# BL808 register map
File version: 0.1
Registers are access not given, no defined reset value unless marked. A register's access mark holds for its fields unless they carry their own. Offsets are from the block's base; [hi:lo] are bit positions; {n}, {i} and the like mark numbered series.

## DSI
Base 0x3001A100
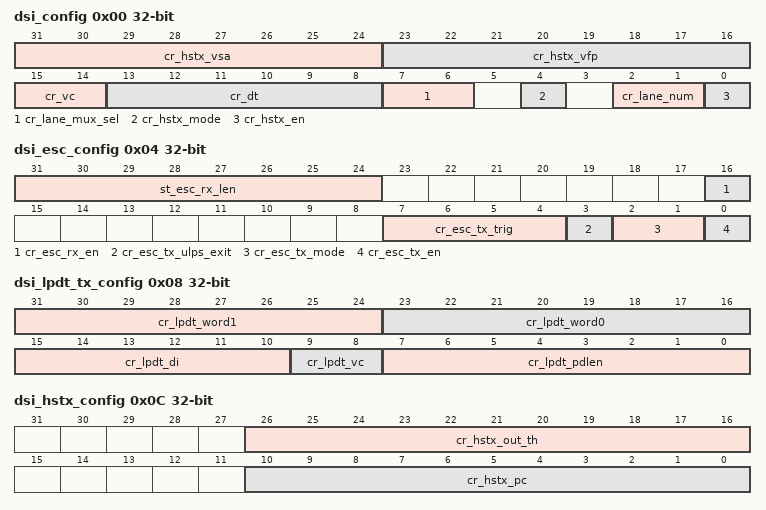
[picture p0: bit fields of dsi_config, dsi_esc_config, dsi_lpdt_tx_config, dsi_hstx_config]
0x00 dsi_config
  [31:24] cr_hstx_vsa rw — HSTX Vertical Sync Active width
  [23:16] cr_hstx_vfp rw — HSTX Vertical Front Porch width
  [15:14] cr_vc rw — Virtual Channel number
  [13:8] cr_dt rw — Data Type 6'h2C: YUV422, 8-bit 6'h0E: RGB565 6'h2E: RGB666, loosely packed 6'h3E: RGB888 Others: Reserved
  [7:6] cr_lane_mux_sel rw — Controls lane order 2'd0: {lane3, lane2, lane1, lane0} (no lane is switched) 2'd1: {lane2, lane1, lane3, lane0} 2'd2: {lane1, lane3, lane2, lane0} 2'd3: {lane3, lane1, lane2, lane0}
  [4] cr_hstx_mode rw — HSTX mode select 1'b0: Sync Event mode 1'b1: Sync Pulse mode
  [2:1] cr_lane_num rw — Lane number configuration 2'd0: 1-lane MIPI TX 2'd1: 2-lane MIPI TX 2'd2: 4-lane MIPI TX 2'd3: Reserved
  [0] cr_hstx_en rw — HSTX function enable signal
0x04 dsi_esc_config
  [31:24] st_esc_rx_len ro — Escape RX length received (Include packet header/data/footer) (unit: byte)
  [16] cr_esc_rx_en rw — Escape RX enable signal
  [7:4] cr_esc_tx_trig rw — Escape TX trigger command
  [3] cr_esc_tx_ulps_exit write-once — Escape TX ULPS exit signal trigger
  [2:1] cr_esc_tx_mode rw — Escape TX mode select 2'd0: LPDT 2'd1: Trigger command 2'd2: ULPS Enable 2'd3: ULPS Disable
  [0] cr_esc_tx_en write-once — Escape TX enable signal
0x08 dsi_lpdt_tx_config rw
  [31:24] cr_lpdt_word1 — LPDT TX word 1
  [23:16] cr_lpdt_word0 — LPDT TX word 0
  [15:10] cr_lpdt_di — LPDT TX data identifier
  [9:8] cr_lpdt_vc — LPDT TX virtual channel
  [7:0] cr_lpdt_pdlen — LPDT TX packet data length (exclude packet header & footer) (unit: byte)
0x0C dsi_hstx_config
  [26:16] cr_hstx_out_th rw — Line buffer threshold for controller to start transmitting each line (unit: pixel) Formula: th = ceil( W * (1 - Fdp*BPP/Fhs/Ln) ) th: cr_hstx_out_th W: Frame width Fdp: Display (dp_dvp_tsrc) clock rate Fhs: DSI byte clock rate (dsi_bit_clk/8 or mipipll_clk/8) BPP: Byte-per-pixel (equals 3 for RGB888 & RGB666; equals 2 for RGB565 & YUV422_8) Ln: DSI lane number (controlled by cr_lane_num) Note: The minimum value is 6 for synchronization concern (Set to 6 if the formula result is negative or less than 6)
  [10:0] cr_hstx_pc rw — Pixel count of each line (frame width) (unit:pixel) Note: Pixel count should not exceed 1280 (720p) and should be a multiple of 4
0x10 dsi_int_status
  [13:0] dsi_int_status ro — [13]: FIFO Error (check 0x60[7:4] for detail) [12]: Pixel Count Too Large Error [11]: Pixel Count Too Small Error [10]: Buffer Underrun Error [9]: Buffer Overrun Error [8]: RX LPDT FIFO ready [7]: TX LPDT FIFO ready [6:3]: RX Trigger Command [2]: RX ULPS Command [1]: RX LPDT End [0]: TX Escape Command End
0x14 dsi_int_mask
  [13:0] dsi_int_mask rw — [13]: FIFO Error (check 0x60[7:4] for detail) [12]: Pixel Count Too Large Error [11]: Pixel Count Too Small Error [10]: Buffer Underrun Error [9]: Buffer Overrun Error [8]: RX LPDT FIFO ready [7]: TX LPDT FIFO ready [6:3]: RX Trigger Command [2]: RX ULPS Command [1]: RX LPDT End [0]: TX Escape Command End
0x18 dsi_int_clear
  [13:0] dsi_int_clear write-once — [13]: FIFO Error (check 0x60[7:4] for detail) [12]: Pixel Count Too Large Error [11]: Pixel Count Too Small Error [10]: Buffer Underrun Error [9]: Buffer Overrun Error [8]: RX LPDT FIFO ready [7]: TX LPDT FIFO ready [6:3]: RX Trigger Command [2]: RX ULPS Command [1]: RX LPDT End [0]: TX Escape Command End
0x1C dsi_int_enable
  [13:0] dsi_int_enable rw — [13]: FIFO Error (check 0x60[7:4] for detail) [12]: Pixel Count Too Large Error [11]: Pixel Count Too Small Error [10]: Buffer Underrun Error [9]: Buffer Overrun Error [8]: RX LPDT FIFO ready [7]: TX LPDT FIFO ready [6:3]: RX Trigger Command [2]: RX ULPS Command [1]: RX LPDT End [0]: TX Escape Command End
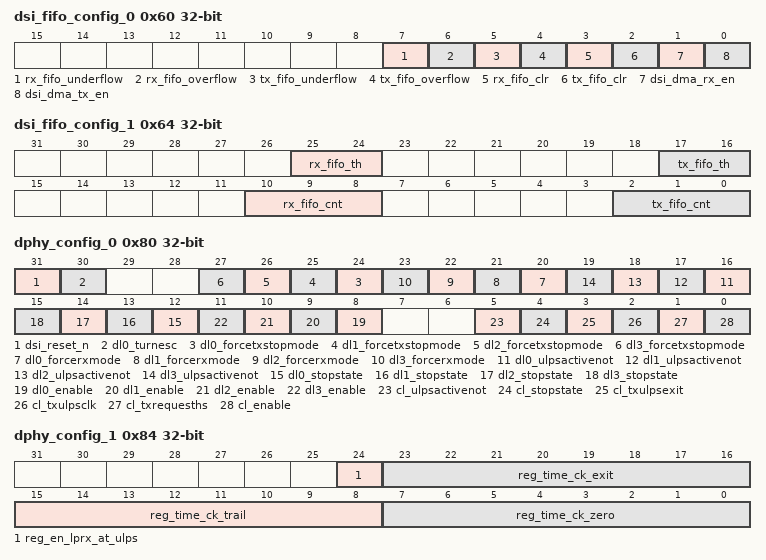
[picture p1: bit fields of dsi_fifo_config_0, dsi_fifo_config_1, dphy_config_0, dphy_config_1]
0x60 dsi_fifo_config_0
  [7] rx_fifo_underflow ro — Underflow flag of RX FIFO, can be cleared by rx_fifo_clr
  [6] rx_fifo_overflow ro — Overflow flag of RX FIFO, can be cleared by rx_fifo_clr
  [5] tx_fifo_underflow ro — Underflow flag of TX FIFO, can be cleared by tx_fifo_clr
  [4] tx_fifo_overflow ro — Overflow flag of TX FIFO, can be cleared by tx_fifo_clr
  [3] rx_fifo_clr write-once — Clear signal of RX FIFO
  [2] tx_fifo_clr write-once — Clear signal of TX FIFO
  [1] dsi_dma_rx_en rw — Enable signal of dma_rx_req/ack interface
  [0] dsi_dma_tx_en rw — Enable signal of dma_tx_req/ack interface
0x64 dsi_fifo_config_1
  [25:24] rx_fifo_th rw — RX FIFO threshold, dma_rx_req will not be asserted if tx_fifo_cnt is less than this value
  [17:16] tx_fifo_th rw — TX FIFO threshold, dma_tx_req will not be asserted if tx_fifo_cnt is less than this value
  [10:8] rx_fifo_cnt ro — RX FIFO available count
  [2:0] tx_fifo_cnt ro — TX FIFO available count
0x68 dsi_fifo_wdata wo
  [31:0] dsi_fifo_wdata
0x6C dsi_fifo_rdata ro
  [31:0] dsi_fifo_rdata
0x80 dphy_config_0
  [31] dsi_reset_n rw — MIPI DSI D-PHY reset pin
  [30] dl0_turnesc write-once — Data lane0 Bus Turnaround
  [n+24] dl{n}_forcetxstopmode rw (n=0..3) — Force Lane{n} to Generate Stop State
  [n+20] dl{n}_forcerxmode rw (n=0..3) — Enables the reverse escape LP receiver. Lane{n} immediately transitions to receive mode.
  [n+16] dl{n}_ulpsactivenot ro (n=0..3) — Data lane{n} is NOT in the ULP state
  [n+12] dl{n}_stopstate ro (n=0..3) — Data lane{n} is in Stop state
  [n+8] dl{n}_enable rw (n=0..3) — Data lane{n} enable
  [5] cl_ulpsactivenot ro — Clock lane is NOT in the ULP state
  [4] cl_stopstate ro — Clock lane is in Stop state
  [3] cl_txulpsexit write-once — Clock lane Transmit ULP Exit Sequence
  [2] cl_txulpsclk rw — Clock lane Transmit Ultra-Low Power State
  [1] cl_txrequesths rw — Clock lane High-Speed Transmit Request
  [0] cl_enable rw — Clock lane enable
0x84 dphy_config_1
  [24] reg_en_lprx_at_ulps rw — MIPI DSI D-PHY control register - reg_en_lprx_at_ulps
  [23:16] reg_time_ck_exit rw — MIPI DSI D-PHY control register - reg_time_ck_exit (tx_clk_esc) txclkesc: 40M, datarate: 800Mbps
  [15:8] reg_time_ck_trail rw — MIPI DSI D-PHY control register - reg_time_ck_trail (tx_clk_esc)
  [7:0] reg_time_ck_zero rw — MIPI DSI D-PHY control register - reg_time_ck_zero (tx_clk_esc)
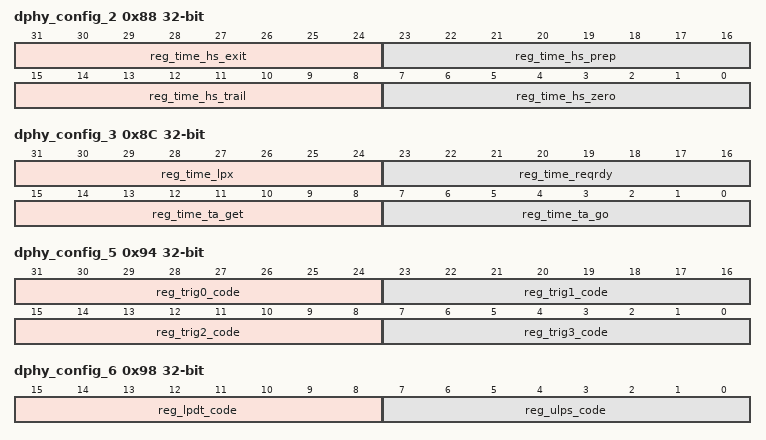
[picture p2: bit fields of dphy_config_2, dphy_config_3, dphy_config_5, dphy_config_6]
0x88 dphy_config_2 rw
  [31:24] reg_time_hs_exit — MIPI DSI D-PHY control register - reg_time_hs_exit (tx_clk_esc)
  [23:16] reg_time_hs_prep — MIPI DSI D-PHY control register - reg_time_hs_prep (tx_clk_esc)
  [15:8] reg_time_hs_trail — MIPI DSI D-PHY control register - reg_time_hs_trail (tx_clk_esc)
  [7:0] reg_time_hs_zero — MIPI DSI D-PHY control register - reg_time_hs_zero (tx_clk_esc)
0x8C dphy_config_3 rw
  [31:24] reg_time_lpx — MIPI DSI D-PHY control register - reg_time_lpx (tx_clk_esc)
  [23:16] reg_time_reqrdy — MIPI DSI D-PHY control register - reg_time_reqrdy
  [15:8] reg_time_ta_get — MIPI DSI D-PHY control register - reg_time_ta_get (tx_clk_esc)
  [7:0] reg_time_ta_go — MIPI DSI D-PHY control register - reg_time_ta_go (tx_clk_esc)
0x90 dphy_config_4
  [15:0] reg_time_wakeup rw — MIPI DSI D-PHY control register - reg_time_wakeup (tx_clk_esc)
0x94 dphy_config_5 rw
  [31-8n:24-8n] reg_trig{n}_code (n=0..3) — MIPI DSI D-PHY control register - reg_trig{n}_code
0x98 dphy_config_6
  [15:8] reg_lpdt_code rw — MIPI DSI D-PHY control register - reg_lpdt_code
  [7:0] reg_ulps_code rw — MIPI DSI D-PHY control register - reg_ulps_code
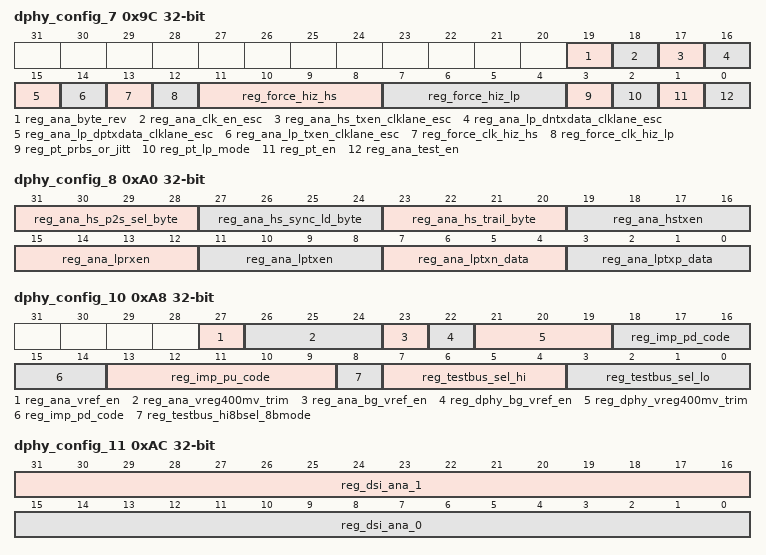
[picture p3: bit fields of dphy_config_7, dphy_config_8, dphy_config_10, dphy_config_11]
0x9C dphy_config_7
  [19] reg_ana_byte_rev rw — MIPI DSI D-PHY control register - reg_ana_byte_rev
  [18] reg_ana_clk_en_esc rw — MIPI DSI D-PHY control register - reg_ana_clk_en_esc
  [17] reg_ana_hs_txen_clklane_esc rw — MIPI DSI D-PHY control register - reg_ana_hs_txen_clklane_esc
  [16] reg_ana_lp_dntxdata_clklane_esc rw — MIPI DSI D-PHY control register - reg_ana_lp_dntxdata_clklane_esc
  [15] reg_ana_lp_dptxdata_clklane_esc rw — MIPI DSI D-PHY control register - reg_ana_lp_dptxdata_clklane_esc
  [14] reg_ana_lp_txen_clklane_esc rw — MIPI DSI D-PHY control register - reg_ana_lp_txen_clklane_esc
  [13] reg_force_clk_hiz_hs rw — MIPI DSI D-PHY control register - reg_force_clk_hiz_hs
  [12] reg_force_clk_hiz_lp rw — MIPI DSI D-PHY control register - reg_force_clk_hiz_lp
  [11:8] reg_force_hiz_hs rw — MIPI DSI D-PHY control register - reg_force_hiz_hs
  [7:4] reg_force_hiz_lp rw — MIPI DSI D-PHY control register - reg_force_hiz_lp
  [3] reg_pt_prbs_or_jitt rw — MIPI DSI D-PHY control register - reg_pt_prbs_or_jitt
  [2] reg_pt_lp_mode rw — MIPI DSI D-PHY control register - reg_pt_lp_mode
  [1] reg_pt_en rw — MIPI DSI D-PHY control register - reg_pt_en
  [0] reg_ana_test_en rw — MIPI DSI D-PHY control register - reg_ana_test_en
0xA0 dphy_config_8 rw
  [31:28] reg_ana_hs_p2s_sel_byte — MIPI DSI D-PHY control register - reg_ana_hs_p2s_sel_byte
  [27:24] reg_ana_hs_sync_ld_byte — MIPI DSI D-PHY control register - reg_ana_hs_sync_ld_byte
  [23:20] reg_ana_hs_trail_byte — MIPI DSI D-PHY control register - reg_ana_hs_trail_byte
  [19:16] reg_ana_hstxen — MIPI DSI D-PHY control register - reg_ana_hstxen
  [15:12] reg_ana_lprxen — MIPI DSI D-PHY control register - reg_ana_lprxen
  [11:8] reg_ana_lptxen — MIPI DSI D-PHY control register - reg_ana_lptxen
  [7:4] reg_ana_lptxn_data — MIPI DSI D-PHY control register - reg_ana_lptxn_data
  [3:0] reg_ana_lptxp_data — MIPI DSI D-PHY control register - reg_ana_lptxp_data
0xA4 dphy_config_9 rw
  [31:0] reg_ana_hs_data_out_byte — MIPI DSI D-PHY control register - reg_ana_hs_data_out_byte
0xA8 dphy_config_10
  [27] reg_ana_vref_en rw — MIPI DSI D-PHY control register - reg_ana_vref_en
  [26:24] reg_ana_vreg400mv_trim rw — MIPI DSI D-PHY control register - reg_ana_vreg400mv_trim
  [23] reg_ana_bg_vref_en rw — MIPI DSI D-PHY control register - reg_ana_bg_vref_en
  [22] reg_dphy_bg_vref_en rw — MIPI DSI D-PHY control register - reg_dphy_bg_vref_en
  [21:19] reg_dphy_vreg400mv_trim rw — MIPI DSI D-PHY control register - reg_dphy_vreg400mv_trim
  [18:14] reg_imp_pd_code rw — MIPI DSI D-PHY control register - reg_imp_pd_code
  [13:9] reg_imp_pu_code rw — MIPI DSI D-PHY control register - reg_imp_pu_code
  [8] reg_testbus_hi8bsel_8bmode rw — MIPI DSI D-PHY control register - reg_testbus_hi8bsel_8bmode
  [7:4] reg_testbus_sel_hi rw — MIPI DSI D-PHY control register - reg_testbus_sel_hi
  [3:0] reg_testbus_sel_lo rw — MIPI DSI D-PHY control register - reg_testbus_sel_lo
0xAC dphy_config_11 rw
  [31:16] reg_dsi_ana_1 — MIPI DSI D-PHY control register - reg_dsi_ana_1
  [15:0] reg_dsi_ana_0 — MIPI DSI D-PHY control register - reg_dsi_ana_0
0xB0 dphy_config_12
  [15:0] reg_dsi_ana_2 rw — MIPI DSI D-PHY control register - reg_dsi_ana_2
0xB4 dphy_config_13
  [15:0] reg_rd_dig_test_bus ro — MIPI DSI D-PHY control register - reg_rd_dig_test_bus
0xB8 dphy_config_14 rw
  [31:0] reg_pt_free_rep_pat — MIPI DSI D-PHY control register - reg_pt_free_rep_pat
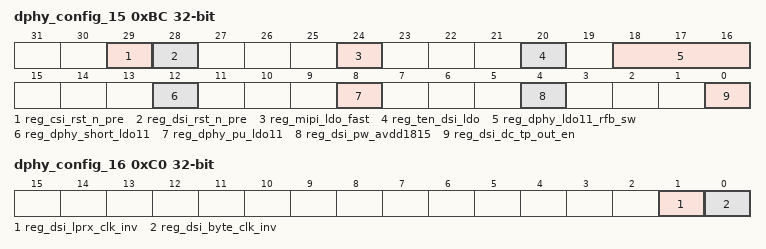
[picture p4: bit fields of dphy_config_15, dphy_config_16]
0xBC dphy_config_15
  [29] reg_csi_rst_n_pre rw — Note: reg_csi_rst_n_pre should be released at least 2 us BEFORE releasing csi_reset_n
  [28] reg_dsi_rst_n_pre rw — Note: reg_dsi_rst_n_pre should be released at least 2 us BEFORE releasing dsi_reset_n
  [24] reg_mipi_ldo_fast rw
  [20] reg_ten_dsi_ldo rw
  [18:16] reg_dphy_ldo11_rfb_sw rw
  [12] reg_dphy_short_ldo11 rw
  [8] reg_dphy_pu_ldo11 rw — enable LDO11 for both dsi and csi
  [4] reg_dsi_pw_avdd1815 rw — 0: power switch on
  [0] reg_dsi_dc_tp_out_en rw
0xC0 dphy_config_16
  [1] reg_dsi_lprx_clk_inv rw, [0] reg_dsi_byte_clk_inv rw
0xFC dummy_reg rw
  [31:0] dummy_reg — Dummy registers
